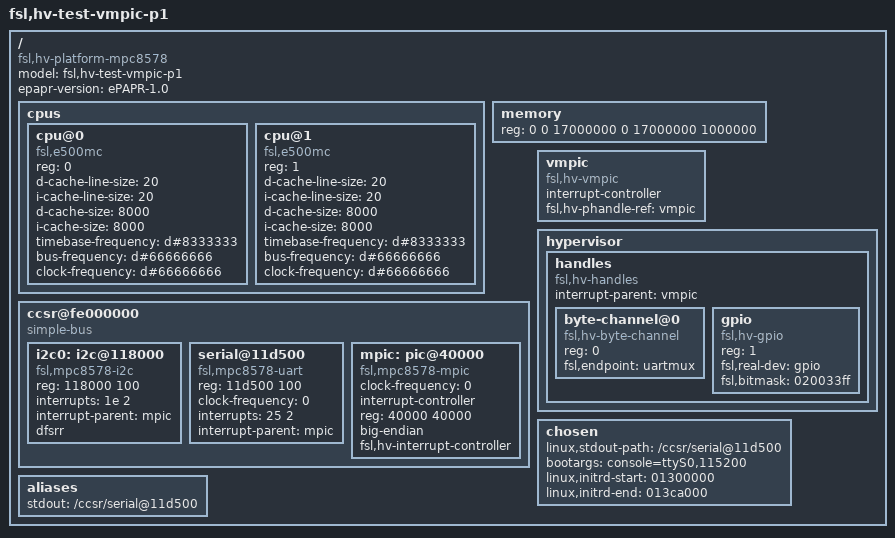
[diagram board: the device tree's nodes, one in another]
/ {
	compatible = "fsl,hv-platform-mpc8578",
                     "fsl,hv-platform";
	model = "fsl,hv-test-vmpic-p1";
	epapr-version = "ePAPR-1.0";
	#address-cells = <2>;
	#size-cells = <1>;

	cpus {
		#address-cells = <1>;
		#size-cells = <0>;

		cpu@0 {
			device_type = "cpu";
			compatible = "fsl,e500mc", "fsl,e500";
			reg = <0>;
			d-cache-line-size = <20>;
			i-cache-line-size = <20>;
			d-cache-size = <8000>;
			i-cache-size = <8000>;
			timebase-frequency = <d#8333333>;
			bus-frequency = <d#66666666>;
			clock-frequency = <d#66666666>;
		};

		cpu@1 {
			device_type = "cpu";
			compatible = "fsl,e500mc", "fsl,e500";
			reg = <1>;
			d-cache-line-size = <20>;
			i-cache-line-size = <20>;
			d-cache-size = <8000>;
			i-cache-size = <8000>;
			timebase-frequency = <d#8333333>;
			bus-frequency = <d#66666666>;
			clock-frequency = <d#66666666>;
		};
	};
	
	memory {
		reg = <0 0 17000000 0 17000000 1000000>;
		device_type = "memory";
	};
	
	ccsr@fe000000 {
		#address-cells = <1>;
		#size-cells = <1>;
		compatible = "simple-bus";
		device_type = "soc";
		ranges = <0 0 fe000000 400000>;

		i2c0: i2c@118000 {
			device_type = "i2c";
			compatible = "fsl,mpc8578-i2c",
			             "fsl,i2c", "fsl-i2c";
			reg = <118000 100>;
			interrupts = <1e 2>;
			interrupt-parent = <&mpic>;
			dfsrr;
		};

		serial@11d500 {
			device_type = "serial";
			compatible = "fsl,mpc8578-uart",
			             "fsl,ns16550", "ns16550";
			reg = <11d500 100>;
			clock-frequency = <0>;
			interrupts = <25 2>;
			interrupt-parent = <&mpic>;
		};

		mpic: pic@40000 {
			clock-frequency = <0>;
			interrupt-controller;
			#address-cells = <0>;
			#interrupt-cells = <2>;
			reg = <40000 40000>;
			compatible = "fsl,mpc8578-mpic", "fsl,mpic",
			             "chrp,open-pic";
			device_type = "open-pic";
			big-endian;
			fsl,hv-interrupt-controller;
		};
	};


	vmpic:vmpic {
		compatible = "fsl,hv-vmpic";
		interrupt-controller;
		fsl,hv-phandle-ref = <&vmpic>;
	};

	hypervisor {
		handles {
			#address-cells = <1>;
			#size-cells = <0>;
			compatible = "fsl,hv-handles";
			interrupt-parent = <&vmpic>;
			
			byte-channel@0 {
				reg = <0>;
				compatible = "fsl,hv-byte-channel";
				fsl,endpoint = "uartmux";
			};
	
			gpio {
				reg = <1>;
				compatible = "fsl,hv-gpio";
				fsl,real-dev = "gpio";
				fsl,bitmask = <020033ff>;
			};
		};
	};

	chosen {
		linux,stdout-path = "/ccsr/serial@11d500";
		bootargs = "console=ttyS0,115200";
		linux,initrd-start = <01300000>;
		linux,initrd-end = <013ca000>;
	};
	
	aliases {
		stdout = "/ccsr/serial@11d500";
	};
};
